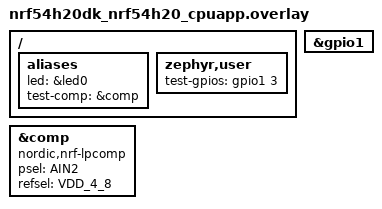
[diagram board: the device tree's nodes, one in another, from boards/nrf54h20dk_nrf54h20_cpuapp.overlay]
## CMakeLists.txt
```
#
# Copyright (c) 2024 Nordic Semiconductor ASA
#
# SPDX-License-Identifier: LicenseRef-Nordic-5-Clause
#

cmake_minimum_required(VERSION 3.20.0)
find_package(Zephyr REQUIRED HINTS $ENV{ZEPHYR_BASE})
zephyr_include_directories(include)

project(lpcomp)

target_sources(app PRIVATE ./../common/main.c)
target_sources(app PRIVATE src/driver_test.c)
```

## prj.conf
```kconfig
CONFIG_COMPARATOR=y
CONFIG_GPIO=y

# Enable runtime power management for peripheral
CONFIG_PM_DEVICE=y
CONFIG_PM_DEVICE_RUNTIME=y

CONFIG_PM=y
CONFIG_PM_S2RAM=y
CONFIG_POWEROFF=y
CONFIG_PM_S2RAM_CUSTOM_MARKING=y
CONFIG_CONSOLE=n
CONFIG_UART_CONSOLE=n
CONFIG_SERIAL=n
CONFIG_POWEROFF=y
CONFIG_BOOT_BANNER=n
CONFIG_ASSERT=y
```

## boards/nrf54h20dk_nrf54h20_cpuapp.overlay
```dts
/*
 * Copyright (c) 2024 Nordic Semiconductor ASA
 *
 * SPDX-License-Identifier: LicenseRef-Nordic-5-Clause
 */

/ {
	aliases {
		led = &led0;
		/delete-property/ led1;
		test-comp = &comp;
	};

	zephyr,user {
		test-gpios = <&gpio1 3 GPIO_ACTIVE_HIGH>;
	};
};

/delete-node/ &led1;

&gpio1 {
	status = "okay";
};

&comp {
	compatible = "nordic,nrf-lpcomp";
	psel = "AIN2"; /* P1.02 */
	refsel = "VDD_4_8";
	status = "okay";
};
```

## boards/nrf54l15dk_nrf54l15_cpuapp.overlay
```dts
/*
 * Copyright (c) 2024 Nordic Semiconductor ASA
 *
 * SPDX-License-Identifier: LicenseRef-Nordic-5-Clause
 */

/ {
	aliases {
		led = &button3;
		test-comp = &comp;
	};

	zephyr,user {
		test-gpios = <&gpio1 10 GPIO_ACTIVE_HIGH>;
	};
};

&gpio1 {
	status = "okay";
};

&comp {
	compatible = "nordic,nrf-lpcomp";
	psel = "AIN4"; /* P1.11 */
	refsel = "VDD_4_8";
	status = "okay";
};
```

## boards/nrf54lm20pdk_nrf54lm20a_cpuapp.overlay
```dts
/*
 * Copyright (c) 2024 Nordic Semiconductor ASA
 *
 * SPDX-License-Identifier: LicenseRef-Nordic-5-Clause
 */

/ {
	aliases {
		led = &led0;
		/delete-property/ led1;
		test-comp = &comp;
	};

	zephyr,user {
		test-gpios = <&gpio1 30 GPIO_ACTIVE_HIGH>;
	};
};

/delete-node/ &led1;

&gpio1 {
	status = "okay";
};

&comp {
	compatible = "nordic,nrf-lpcomp";
	psel = "AIN1"; /* P1.31 */
	refsel = "VDD_4_8";
	status = "okay";
};
```

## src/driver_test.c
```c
/*
 * Copyright (c) 2024 Nordic Semiconductor ASA
 *
 * SPDX-License-Identifier: LicenseRef-Nordic-5-Clause
 */

#include <zephyr/drivers/comparator.h>
#include <zephyr/drivers/gpio.h>
#include <zephyr/kernel.h>

static const struct device *test_dev = DEVICE_DT_GET(DT_ALIAS(test_comp));
static const struct gpio_dt_spec test_pin = GPIO_DT_SPEC_GET(DT_PATH(zephyr_user), test_gpios);

volatile int counter;

static void test_callback(const struct device *dev, void *user_data)
{
	counter++;
}

void thread_definition(void)
{
	int rc;

	gpio_pin_configure_dt(&test_pin, GPIO_OUTPUT_INACTIVE);

	rc = comparator_set_trigger_callback(test_dev, test_callback, NULL);
	__ASSERT_NO_MSG(rc == 0);

	rc = comparator_set_trigger(test_dev, COMPARATOR_TRIGGER_BOTH_EDGES);
	__ASSERT_NO_MSG(rc == 0);
	k_msleep(10);

	while (1) {
		counter = 0;
		gpio_pin_set_dt(&test_pin, 1);
		k_msleep(10);
		__ASSERT_NO_MSG(counter == 1);
		gpio_pin_set_dt(&test_pin, 0);
		k_msleep(10);
		__ASSERT_NO_MSG(counter == 2);
	}
};
```
